# NAVSS0_MCRC_0_ALIAS64K_MCRC0_S_CFG_MCRC64 register map
Vendor: Texas Instruments
Peripheral module from a debugger description file (folder J721S2).
Registers are 32-bit, read-write, reset 0x0 unless marked. A register's access mark holds for its fields unless they carry their own. Offsets are as the file gives them; lines under a group give offsets from that group; [hi:lo] are bit positions; {n}, {i} and the like mark numbered series; 'fields as' and 'values as' point back to an identical list; <NAME> marks a mode.

## NAVSS0_MCRC_0_ALIAS64K_MCRC0_S_CFG_MCRC64
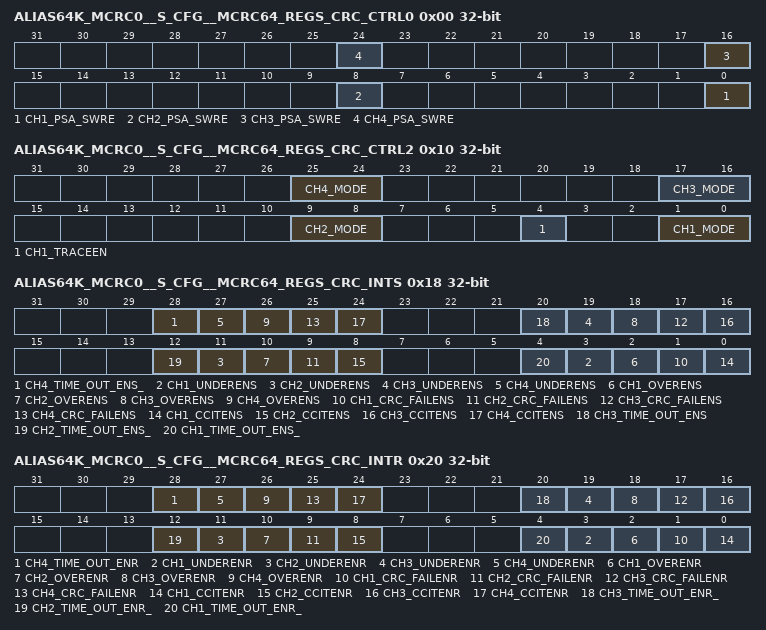
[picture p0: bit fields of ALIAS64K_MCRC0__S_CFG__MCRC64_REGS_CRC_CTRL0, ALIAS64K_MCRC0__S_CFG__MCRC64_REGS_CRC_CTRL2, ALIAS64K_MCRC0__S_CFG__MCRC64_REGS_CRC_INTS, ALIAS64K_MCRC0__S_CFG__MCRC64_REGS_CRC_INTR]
0x00 ALIAS64K_MCRC0__S_CFG__MCRC64_REGS_CRC_CTRL0 — CRC Global Control Register 0
  [8n-8] CH{n}_PSA_SWRE (n=1..4) — Channel {n} PSA Software Reset. When set, the PSA Signature Register is reset to all zero. Software reset does not reset software reset bit itself. Therefore, CPU is required to clear this bit by writing a 0 . 0 = PSA Signature Register not reset 1 = PSA Signature Register reset
0x08 ALIAS64K_MCRC0__S_CFG__MCRC64_REGS_CRC_CTRL1 — CRC Global Control Register 1
  [0] PWDN — Power Down. When set, MCRC moduleMCRC Module is put in power down mode. 0 = MCRC is not in power down mode. 1 = MCRC is in power down mode.
0x10 ALIAS64K_MCRC0__S_CFG__MCRC64_REGS_CRC_CTRL2 — Data capture mode is especially useful when it is used in conjunction when data trace (CH1_TRACEEN) for channel 1. The seed value can be planted in PSA Signature Register during data capture mode by writing a seed value into PSA Signature Register. Data trace enable bit is then set to snoop and compress any read transaction on Data buses. When trace enable bit is set, CH1_MODE is automatically reset to data capture mode. To change mode from one to another in the middle of an on-going mode user should take the following steps:
  [25:24] CH4_MODE — Channel 4 Mode. 00 = Data Capture mode. In this mode, the PSA Signature Register does not compress data when it is written. Any data written to PSA Signature Register is simply captured by PSA Signature Register without any compression. This mode can be used to plant seed value into the PSA register. 01 = AUTO mode 10 = Semi-CPU mode 11 = Full-CPU mode For all four channels the seed value can be first planted into PSA register before the Channel Mode is switched to Full-CPU mode since host CPU controls the amount of data for compression. During AUTO mode, the PSA register is automatically reset to zero at the end of each sector compression.
  [17:16] CH3_MODE — Channel 3 Mode. 00 = Data Capture mode. In this mode, the PSA Signature Register does not compress data when it is written. Any data written to PSA Signature Register is simply captured by PSA Signature Register without any compression. This mode can be used to plant seed value into the PSA register. 01 = AUTO mode 10 = Semi-CPU mode 11 = Full-CPU mode
  [9:8] CH2_MODE — Channel 2 Mode. 00 = Data Capture mode. In this mode, the PSA Signature Register does not compress data when it is written. Any data written to PSA Signature Register is simply captured by PSA Signature Register without any compression. This mode can be used to plant seed value into the PSA register. 01 = AUTO mode 10 = Semi-CPU mode 11 = Full-CPU mode
  [4] CH1_TRACEEN — Channel 1 Data Trace Enable When set, the channel is put into data trace mode. The channel snoops on the CPU VBUSM, ITCM, DTCM buses for any read transaction. Any read data on these buses is compressed by the PSA Signature Register. When suspend is on, the PSA Signature Register does not compress any read data on these buses. 0 = Data Trace disable 1 = Data Trace enable
  [1:0] CH1_MODE — Channel 1 Mode. 00 = Data Capture mode. In this mode, the PSA Signature Register does not compress data when it is written. Any data written to PSA Signature Register is simply captured by PSA Signature Register without any compression. This mode can be used to plant seed value into the PSA register. 01 = AUTO mode 10 = Semi-CPU mode 11 = Full-CPU mode
0x18 ALIAS64K_MCRC0__S_CFG__MCRC64_REGS_CRC_INTS access not given — CRC Interrupt Enable Set Register
  [28] CH4_TIME_OUT_ENS_ — Channel 4 Timeout Interrupt Enable Bit Writing a one to this bit enable the timeout interrupt. Writing a zero has no effect. Reading from this bit gives the status (interrupt enable/disable). User and privileged mode read: 0 = Timeout Interrupt disable 1 = Timeout Interrupt enable User and privileged mode write: 0 = Has no effect 1 = Timeout Interrupt enable (access R/W1TS)
  [8n-5] CH{n}_UNDERENS (n=1..4) — Channel {n} Underrun Interrupt Enable Bit Writing a one to this bit enable the underrun interrupt. Writing a zero has no effect. Reading from this bit gives the status (interrupt enable/disable). User and privileged mode read: 0 = Underrun Interrupt disable 1 = Underrun Interrupt enable User and privileged mode write: 0 = Has no effect 1 = Underrun Interrupt enable (access R/W1TS)
  [8n-6] CH{n}_OVERENS (n=1..4) — Channel {n} Overrun Interrupt Enable Bit Writing a one to this bit enable the overrun interrupt. Writing a zero has no effect. Reading from this bit gives the status (interrupt enable/disable). User and privileged mode read: 0 = Overrun Interrupt disable 1 = Overrun Interrupt enable User and privileged mode write: 0 = Has no effect 1 = Overrun Interrupt enable (access R/W1TS)
  [8n-7] CH{n}_CRC_FAILENS (n=1..4) — Channel {n} CRC Fail Interrupt Enable Bit. Writing a one to this bit enable the CRC fail interrupt. Writing a zero has no effect. Reading from this bit gives the status (interrupt enable/disable). User and privileged mode read: 0 = CRC Fail Interrupt disable 1 = CRC Fail Interrupt enable User and privileged mode write: 0 = Has no effect 1 = CRC Fail Interrupt enable (access R/W1TS)
  [8n-8] CH{n}_CCITENS (n=1..4) — Channel {n} Compression Complete Interrupt Enable Bit. Writing a one to this bit enable the CRC fail interrupt. Writing a zero has no effect. Reading from this bit gives the status (interrupt enable/disable). User and privileged mode read: 0 = Compression Complete Interrupt disable 1 = Compression Complete Interrupt enable User and privileged mode write: 0 = Has no effect 1 = Compression Complete Interrupt enable (access R/W1TS)
  [20] CH3_TIME_OUT_ENS — Channel 3 Timeout Interrupt Enable Bit Writing a one to this bit enable the timeout interrupt. Writing a zero has no effect. Reading from this bit gives the status (interrupt enable/disable). User and privileged mode read: 0 = Timeout Interrupt disable 1 = Timeout Interrupt enable User and privileged mode write: 0 = Has no effect 1 = Timeout Interrupt enable (access R/W1TS)
  [12] CH2_TIME_OUT_ENS_ — Channel 2 Timeout Interrupt Enable Bit Writing a one to this bit enable the timeout interrupt. Writing a zero has no effect. Reading from this bit gives the status (interrupt enable/disable). User and privileged mode read: 0 = Timeout Interrupt disable 1 = Timeout Interrupt enable User and privileged mode write: 0 = Has no effect 1 = Timeout Interrupt enable (access R/W1TS)
  [4] CH1_TIME_OUT_ENS_ — Channel 1 Timeout Interrupt Enable Bit Writing a one to this bit enable the timeout interrupt. Writing a zero has no effect. Reading from this bit gives the status (interrupt enable/disable). User and privileged mode read: 0 = Timeout Interrupt disable 1 = Timeout Interrupt enable User and privileged mode write: 0 = Has no effect 1 = Timeout Interrupt enable (access R/W1TS)
0x20 ALIAS64K_MCRC0__S_CFG__MCRC64_REGS_CRC_INTR access not given — CRC Interrupt Enable Reset Register
  [28] CH4_TIME_OUT_ENR — Channel 4 Timeout Interrupt Disable Bit Writing a one to this bit disable the timeout interrupt. Writing a zero has no effect. Reading from this bit gives the status (interrupt enable/disable). User and privileged mode read: 0 = Timeout Interrupt disable 1 = Timeout Interrupt enable User and privileged mode write: 0 = Has no effect 1 = Timeout Interrupt enable (access R/W1TC)
  [8n-5] CH{n}_UNDERENR (n=1..4) — Channel {n} Underrun Interrupt Disable Bit Writing a one to this bit disable the underrun interrupt. Writing a zero has no effect. Reading from this bit gives the status (interrupt enable/disable). User and privileged mode read: 0 = Underrun Interrupt disable 1 = Underrun Interrupt enable User and privileged mode write: 0 = Has no effect 1 = Underrun Interrupt enable (access R/W1TC)
  [8n-6] CH{n}_OVERENR (n=1..4) — Channel {n} Overrun Interrupt Disable Bit Writing a one to this bit disable the overrun interrupt. Writing a zero has no effect. Reading from this bit gives the status (interrupt enable/disable). User and privileged mode read: 0 = Overrun Interrupt disable 1 = Overrun Interrupt enable User and privileged mode write: 0 = Has no effect 1 = Overrun Interrupt enable (access R/W1TC)
  [8n-7] CH{n}_CRC_FAILENR (n=1..4) — Channel {n} CRC Fail Interrupt Disable Bit. Writing a one to this bit disable the CRC fail interrupt. Writing a zero has no effect. Reading from this bit gives the status (interrupt enable/disable). User and privileged mode read: 0 = CRC Fail Interrupt disable 1 = CRC Fail Interrupt enable User and privileged mode write: 0 = Has no effect 1 = CRC Fail Interrupt enable (access R/W1TC)
  [8n-8] CH{n}_CCITENR (n=1..4) — Channel {n} Compression Complete Interrupt Disable Bit Writing a one to this bit disable the CRC fail interrupt. Writing a zero has no effect. Reading from this bit gives the status (interrupt enable/disable) User and privileged mode read: 0 = Compression Complete Interrupt disable 1 = Compression Complete Interrupt enable User and privileged mode write: 0 = Has no effect 1 = Compression Complete Interrupt disable (access R/W1TC)
  [20] CH3_TIME_OUT_ENR_ — Channel 3 Timeout Interrupt Disable Bit Writing a one to this bit disable the timeout interrupt. Writing a zero has no effect. Reading from this bit gives the status (interrupt enable/disable). User and privileged mode read: 0 = Timeout Interrupt disable 1 = Timeout Interrupt enable User and privileged mode write: 0 = Has no effect 1 = Timeout Interrupt enable (access R/W1TC)
  [12] CH2_TIME_OUT_ENR_ — Channel 2 Timeout Interrupt Disable Bit Writing a one to this bit disable the timeout interrupt. Writing a zero has no effect. Reading from this bit gives the status (interrupt enable/disable). User and privileged mode read: 0 = Timeout Interrupt disable 1 = Timeout Interrupt enable User and privileged mode write: 0 = Has no effect 1 = Timeout Interrupt enable (access R/W1TC)
  [4] CH1_TIME_OUT_ENR_ — Channel 1 Timeout Interrupt Disable Bit Writing a one to this bit disable the timeout interrupt. Writing a zero has no effect. Reading from this bit gives the status (interrupt enable/disable). User and privileged mode read: 0 = Timeout Interrupt disable 1 = Timeout Interrupt enable User and privileged mode write: 0 = Has no effect 1 = Timeout Interrupt enable (access R/W1TC)
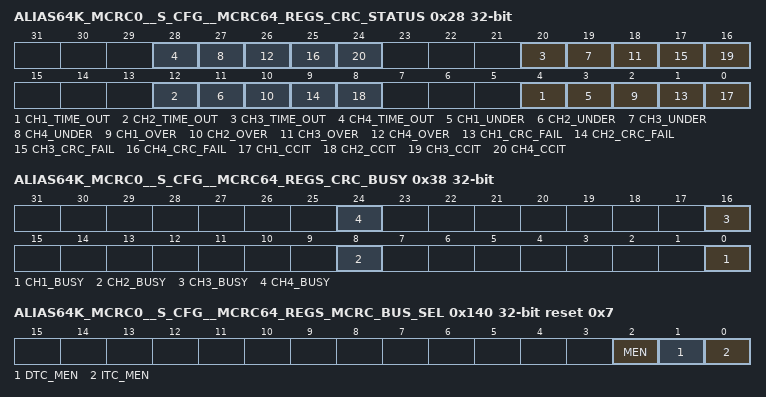
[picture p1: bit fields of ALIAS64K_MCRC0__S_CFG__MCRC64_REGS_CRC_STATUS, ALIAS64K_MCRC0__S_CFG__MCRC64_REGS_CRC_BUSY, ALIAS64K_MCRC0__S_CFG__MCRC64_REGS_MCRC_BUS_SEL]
0x28 ALIAS64K_MCRC0__S_CFG__MCRC64_REGS_CRC_STATUS access not given — CRC Interrupt Status Register
  [8n-4] CH{n}_TIME_OUT (n=1..4) — Channel {n} CRC Timeout Status Flag This bit is cleared by writing a 1 to it only. Writing 0 has no effect. This bit is set in AUTO mode. 0 = No timeout interrupt is active 1 = Timeout interrupt is active (access R/W1TC)
  [8n-5] CH{n}_UNDER (n=1..4) — Channel {n} CRC Underrun Status Flag. This bit is cleared by writing a 1 to it only. Writing 0 has no effect. This bit is set in AUTO mode only 0 = No underrun interrupt is active 1 = Underrun interrupt is active (access R/W1TC)
  [8n-6] CH{n}_OVER (n=1..4) — Channel {n} CRC Overrun Status Flag This bit is cleared by writing a 1 to it only. Writing 0 has no effect. This bit is set in AUTO mode 0 = No overrun interrupt is active 1 = Overrun interrupt is active (access R/W1TC)
  [8n-7] CH{n}_CRC_FAIL (n=1..4) — Channel {n} CRC Compare Fail Status Flag. This bit is cleared by writing a 1 to it only. Writing 0 has no effect. This bit is set in AUTO mode only. 0 = No CRC compare fail interrupt is active 1 = CRC compare fail interrupt is active (access R/W1TC)
  [8n-8] CH{n}_CCIT (n=1..4) — Channel {n} CRC Pattern Compression Complete Status Flag. This bit is cleared by writing a 1 to it only. Writing 0 has no effect. This bit is only set in Semi-CPU mode. 0 = No CRC pattern compression complete interrupt is active 1 = CRC pattern compression complete interrupt is active (access R/W1TC)
0x30 ALIAS64K_MCRC0__S_CFG__MCRC64_REGS_CRC_INT_OFFSET_REG ro — CRC Interrupt Offset
  [7:0] CRC — Interrupt Offset. This register indicates the highest priority pending interrupt vector address. Reading the offset register automatically clears the respective interrupt flag.
0x38 ALIAS64K_MCRC0__S_CFG__MCRC64_REGS_CRC_BUSY ro — CRC Busy Register
  [8n-8] CH{n}_BUSY (n=1..4) — During AUTO or Semi-CPU mode, the busy flag is set when the first data pattern of the block is compressed and remains set until the the last data pattern of the block is compressed. The flag is cleared when the last data pattern of the block is compressed.
0x40 ALIAS64K_MCRC0__S_CFG__MCRC64_REGS_CRC_PCOUNT_REG1 — CRC Pattern Counter Preload Register1
  [19:0] CRC_PAT_COUNT1 — Channel 1 Pattern Counter Preload Register. This register contains the number of data patterns in one sector to be compressed before a CRC is performed.
{0x4+0x40*i} ALIAS64K_MCRC0__S_CFG__MCRC64_REGS_CRC_SCOUNT_REG{i} (i=1..4) — CRC Sector Counter Preload Register{i}
  [15:0] CRC_SEC_COUNT{i} — Channel {i} Sector Counter Preload Register. This register contains the number of sectors in one block of memory.
{0x8+0x40*i} ALIAS64K_MCRC0__S_CFG__MCRC64_REGS_CRC_CURSEC_REG{i} ro (i=1..3) — CRC Current Sector Register {i}
  [15:0] CRC_CURSEC{i} — Channel {i} Current Sector ID Register. In AUTO mode, this register contains the current sector number of which the signature verification fails. The sector counter is a free running up counter. When a sector fails, the erroneous sector number is logged into current sector ID register and the CRC fail interrupt is generated The sector ID register is frozen until it is read and the CRC fail status bit is cleared by CPU. While it is frozen, it does not capture another erroneous sector number. When this condition happens, an overrun interrupt is generated instead. Once the register is read and the CRC fail interrupt flag is cleared it can capture new erroneous sector number.
0x4C ALIAS64K_MCRC0__S_CFG__MCRC64_REGS_CRC_WDTOPLD1 — CRC channel 1 Watchdog Timeout Preload Register A
  [23:0] CRC_WDTOPLD1 — Channel 1 Watchdog Timeout Counter Preload Register. This register contains the number of clock cycles within which the DMA must transfer the next block of data patterns.
0x50 ALIAS64K_MCRC0__S_CFG__MCRC64_REGS_CRC_BCTOPLD1 — CRC channel 1 Block Complete Timeout Preload Register B
  [23:0] CRC_BCTOPLD1 — Channel 1 Block Complete Timeout Counter Preload Register. This register contains the number of clock cycles within which the CRC for an entire block needs to complete before a timeout interrupt is generated.
{0x20+0x40*i} ALIAS64K_MCRC0__S_CFG__MCRC64_REGS_PSA_SIGREGL{i} (i=1..3) — Channel {i} PSA signature low register
  [31:0] PSASIG{i} — Channel {i} PSA Signature Low Register. This register contains the value stored at PSASIG{i}[31:0] register.
{0x24+0x40*i} ALIAS64K_MCRC0__S_CFG__MCRC64_REGS_PSA_SIGREGH{i} (i=1..3) — Channel {i} PSA signature high register
  [31:0] PSASIG{i}_63_32 — Channel {i} PSA Signature High Register. This register contains the value stored at PSASIG{i}[63:32] register.
{0x28+0x40*i} ALIAS64K_MCRC0__S_CFG__MCRC64_REGS_CRC_REGL{i} (i=1..3) — Channel {i} CRC value low register
  [31:0] CRC{i} — Channel {i} CRC Value Low Register. This register contains the current known good signature value stored at CRC{i}[31:0] register.
0x6C ALIAS64K_MCRC0__S_CFG__MCRC64_REGS_CRC_REGH1 — Channel 1 CRC value high register
  [31:0] CRC1_47_32 — Channel 1 CRC Value High Register. This register contains the current known good signature value stored at CRC1[63:32] register.
{0x30+0x40*i} ALIAS64K_MCRC0__S_CFG__MCRC64_REGS_PSA_SECSIGREGL{i} ro (i=1..3) — Channel {i} PSA sector signature low register
  [31:0] PSASECSIG{i} — Channel {i} PSA Sector Signature Low Register. This register contains the value stored at PSASECSIG{i}[31:0] register.
{0x34+0x40*i} ALIAS64K_MCRC0__S_CFG__MCRC64_REGS_PSA_SECSIGREGH{i} ro (i=1..4) — Channel {i} PSA sector signature high register
  [31:0] PSASECSIG{i}_63_32 — Channel {i} PSA Sector Signature High Register. This register contains the value stored at PSASECSIG{i}[63:32] register.
{0x38+0x40*i} ALIAS64K_MCRC0__S_CFG__MCRC64_REGS_RAW_DATAREGL{i} ro (i=1..4) — Channel {i} Raw Data Low Register
  [31:0] RAW_DATA{i} — Channel {i} Raw Data Low Register. This register contains bit 31:0 of the uncompressed raw data.
0x7C ALIAS64K_MCRC0__S_CFG__MCRC64_REGS_RAW_DATAREGH1 ro — Channel 1 Raw Data High Register
  [31:0] RAW_DATA1_47_32 — Channel 1 Raw Data High Register. This register contains bit 63:32 of the uncompressed raw data.
0x80 ALIAS64K_MCRC0__S_CFG__MCRC64_REGS_CRC_PCOUNT_REG2 — CRC Pattern Counter Preload Register2
  [19:0] CRC_PAT_COUNT2 — CRC Pattern Counter Preload Register 2 This register contains the number of data patterns in one sector to be compressed before a CRC is performed.
0x8C ALIAS64K_MCRC0__S_CFG__MCRC64_REGS_CRC_WDTOPLD2 — CRC channel 2 Watchdog Timeout Preload Register
  [23:0] CRC_WDTOPLD2 — Channel 2 Watchdog Timeout Counter Preload Register. This register contains the number of clock cycles within which the DMA must transfer the next block of data patterns.
0x90 ALIAS64K_MCRC0__S_CFG__MCRC64_REGS_CRC_BCTOPLD2 — CRC channel 2 Block Complete Timeout Preload Register
  [23:0] CRC_BCTOPLD2 — Channel 2 Block Complete Timeout Counter Preload Register. This register contains the number of clock cycles within which the CRC of an entire block needs to complete before a timeout interrupt is generated.
0xAC ALIAS64K_MCRC0__S_CFG__MCRC64_REGS_CRC_REGH2 — Channel 2 CRC value high register
  [31:0] CRC2_63_32 — Channel 2 CRC Value High Register. This register contains the current known good signature value stored at CRC2[63:32] register.
{0x3C+0x40*i} ALIAS64K_MCRC0__S_CFG__MCRC64_REGS_RAW_DATAREGH{i} ro (i=2..4) — Channel {i} Raw Data High Register
  [31:0] RAW_DATA{i}_63_32 — Channel {i} Raw Data High Register. This register contains bit 63:32 of the uncompressed raw data.
0xC0 ALIAS64K_MCRC0__S_CFG__MCRC64_REGS_CRC_PCOUNT_REG3 — CRC Pattern Counter Preload Register3
  [19:0] CRC_PAT_COUNT3 — Channel 3 Pattern Counter Preload Register. This register contains the number of data patterns in one sector to be compressed before a CRC is performed.
0xCC ALIAS64K_MCRC0__S_CFG__MCRC64_REGS_CRC_WDTOPLD3 — CRC channel 3 Watchdog Timeout Preload Register
  [23:0] CRC_WDTOPLD3 — Channel 3 Watchdog Timeout Counter Preload Register. This register contains the number of clock cycles within which the DMA must transfer the next block of data patterns.
0xD0 ALIAS64K_MCRC0__S_CFG__MCRC64_REGS_CRC_BCTOPLD3 — CRC channel 3 Block Complete Timeout Preload Register
  [23:0] CRC_BCTOPLD3 — Channel 3 Block Complete Timeout Counter Preload Register. This register contains the number of clock cycles within which the CRC of an entire block needs to complete before a timeout interrupt is generated.
0xEC ALIAS64K_MCRC0__S_CFG__MCRC64_REGS_CRC_REGH3 — Channel 3 CRC value high register
  [31:0] CRC3_63_32 — Channel 3 CRC Value High Register. This register contains the current known good signature value stored at CRC3[63:32] register.
0x100 ALIAS64K_MCRC0__S_CFG__MCRC64_REGS_CRC_PCOUNT_REG4 — CRC Pattern Counter Preload Register4
  [19:0] CRC_PAT_COUNT4 — Channel 4 Pattern Counter Preload Register. This register contains the number of data patterns in one sector to be compressed before a CRC is performed.
0x108 ALIAS64K_MCRC0__S_CFG__MCRC64_REGS_CRC_CURSEC_REG4 ro — CRC Current Sector Register 4
  [15:0] CRC_CURSEC4 — In AUTO mode, this register contains the current sector number of which the signature verification fails. The sector counter is a free running up counter. When a sector fails, the erroneous sector number is logged into current sector ID register and the CRC fail interrupt is generated The sector ID register is frozen until it is read and the CRC fail status bit is cleared by CPU. While it is frozen, it does not capture another erroneous sector number. When this condition happens, an overrun interrupt is generated instead. Once the register is read and the CRC fail interrupt flag is cleared it can capture new erroneous sector number. In Semi-CPU mode, this register is used to indicate the sector number for which the compression complete has last happened.
0x10C ALIAS64K_MCRC0__S_CFG__MCRC64_REGS_CRC_WDTOPLD4 — CRC channel 4 Watchdog Timeout Preload Register
  [23:0] CRC_WDTOPLD4 — This register contains the number of clock cycles within which the DMA must transfer the next block of data patterns.
0x110 ALIAS64K_MCRC0__S_CFG__MCRC64_REGS_CRC_BCTOPLD4 — CRC channel 4 Block Complete Timeout Preload Register
  [23:0] CRC_BCTOPLD4 — This register contains the number of clock cycles within which the CRC of an entire block needs to complete before a timeout interrupt is generated.
0x120 ALIAS64K_MCRC0__S_CFG__MCRC64_REGS_PSA_SIGREGL4 — Channel 4 PSA signature low register
  [31:0] PSASIG4 — This register contains the value stored at PSASIG4[31:0] register.
0x124 ALIAS64K_MCRC0__S_CFG__MCRC64_REGS_PSA_SIGREGH4 — Channel 4 PSA signature high register
  [31:0] PSASIG4_63_32 — This register contains the value stored at PSASIG4[63:32] register.
0x128 ALIAS64K_MCRC0__S_CFG__MCRC64_REGS_CRC_REGL4 — Channel 4 CRC value low register
  [31:0] CRC4 — Channel 4 CRC Value Low Register.
0x12C ALIAS64K_MCRC0__S_CFG__MCRC64_REGS_CRC_REGH4 — Channel 4 CRC value high register
  [31:0] CRC4_63_32 — Channel 4 CRC Value High Register.
0x130 ALIAS64K_MCRC0__S_CFG__MCRC64_REGS_PSA_SECSIGREGL4 ro — Channel 4 PSA sector signature low register
  [31:0] PSASECSIG4 — Channel 4 PSA Sector Signature Low Register.
0x140 ALIAS64K_MCRC0__S_CFG__MCRC64_REGS_MCRC_BUS_SEL reset 0x7 — Data bus tracing selection
  [2] MEN — Enable/disables the tracing of VBUSM 0: Tracing of VBUSM master bus has been disabled 1: Tracing of VBUSM master bus has been enabled
  [1] DTC_MEN — Enable/disables the tracing of data TCM 0: Tracing of DTCM_ODD and DTCM_EVEN buses have been disabled 1: Tracing of DTCM_ODD and DTCM_EVEN buses have been enabled
  [0] ITC_MEN — Enable/disables the tracing of instruction TCM 0: Tracing of ITCM bus has been disabled 1: Tracing of ITCM bus has been enabled Please refer the description of CPU Data trace at page 1-21 for the priority between different data buses.
{0x180+0x80*i} ALIAS64K_MCRC0__S_CFG__MCRC64_REGS_I0_PSA_SIGREG{i}_CPY wo (i=1..4) — Region for Channel {i} PSA signature block used by DMA based systems.
  [31:0] I0_PSASIG{i}_CPY0 — This register is a 128 byte block copy of the PSASIG{i} register for DMA destination, it is write only, the result can be found in the PSASIG{i} register.
